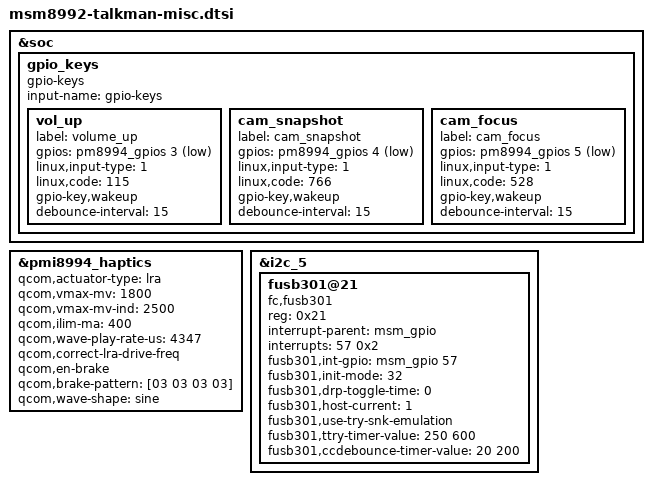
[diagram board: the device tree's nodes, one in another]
/* Copyright (c) 2015, LGE Inc. All rights reserved.
 * Copyright (c) 2014, The Linux Foundation. All rights reserved.
 *
 * This program is free software; you can redistribute it and/or modify
 * it under the terms of the GNU General Public License version 2 and
 * only version 2 as published by the Free Software Foundation.
 *
 * This program is distributed in the hope that it will be useful,
 * but WITHOUT ANY WARRANTY; without even the implied warranty of
 * MERCHANTABILITY or FITNESS FOR A PARTICULAR PURPOSE.  See the
 * GNU General Public License for more details.
 */

&soc {
	gpio_keys {
		compatible = "gpio-keys";
		input-name = "gpio-keys";

		vol_up {
			label = "volume_up";
			gpios = <&pm8994_gpios 3 0x1>;
			linux,input-type = <1>;
			linux,code = <115>;
			gpio-key,wakeup;
			debounce-interval = <15>;
		};

		cam_snapshot {
			label = "cam_snapshot";
			gpios = <&pm8994_gpios 4 0x1>;
			linux,input-type = <1>;
			linux,code = <766>;
			gpio-key,wakeup;
			debounce-interval = <15>;
		};

		cam_focus {
			label = "cam_focus";
			gpios = <&pm8994_gpios 5 0x1>;
			linux,input-type = <1>;
			linux,code = <528>;
			gpio-key,wakeup;
			debounce-interval = <15>;
		};
	};
};

&pmi8994_haptics {
	status = "okay";
	qcom,actuator-type = "lra";
	qcom,vmax-mv = <1800>;
	qcom,vmax-mv-ind = <2500>;
	qcom,ilim-ma = <400>;
	qcom,wave-play-rate-us = <4347>;
	qcom,correct-lra-drive-freq;
	qcom,en-brake;
	qcom,brake-pattern = [03 03 03 03];
	qcom,wave-shape = "sine";
};
//whatfuck is this, does it work?
&i2c_5 {
	fusb301@21 {
		status = "ok";
		compatible = "fc,fusb301";
		reg = <0x21>;
		interrupt-parent = <&msm_gpio>;
		interrupts = <57 0x2>;
		fusb301,int-gpio = <&msm_gpio 57 0>;
		fusb301,init-mode = /bits/ 8 <32>;
		fusb301,drp-toggle-time = /bits/ 8 <0>;
		fusb301,host-current = /bits/ 8 <1>;
		fusb301,use-try-snk-emulation;
		fusb301,ttry-timer-value = <250 600>;
		fusb301,ccdebounce-timer-value = <20 200>;

	};
};
